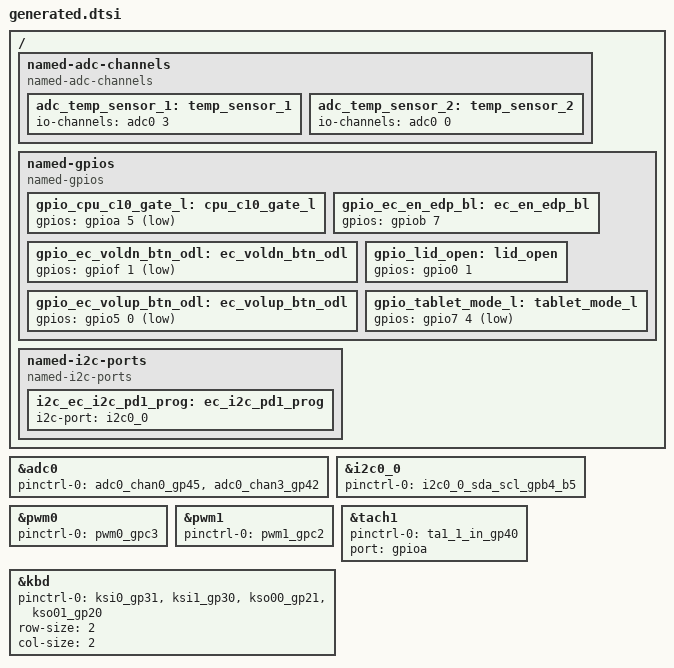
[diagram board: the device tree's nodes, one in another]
/* Copyright 2026 The ChromiumOS Authors
 * Use of this source code is governed by a BSD-style license that can be
 * found in the LICENSE file.
 *
 * This file is auto-generated - do not edit!
 */

/ {

	named-adc-channels {
		compatible = "named-adc-channels";

		adc_temp_sensor_1: temp_sensor_1 {
			io-channels = <&adc0 3>;
		};
		adc_temp_sensor_2: temp_sensor_2 {
			io-channels = <&adc0 0>;
		};
	};

	named-gpios {
		compatible = "named-gpios";

		gpio_cpu_c10_gate_l: cpu_c10_gate_l {
			gpios = <&gpioa 5 (GPIO_INPUT | GPIO_ACTIVE_LOW)>;
		};
		gpio_ec_en_edp_bl: ec_en_edp_bl {
			gpios = <&gpiob 7 (GPIO_OUTPUT | GPIO_ACTIVE_HIGH | GPIO_OUTPUT_INIT_HIGH)>;
		};
		gpio_ec_voldn_btn_odl: ec_voldn_btn_odl {
			gpios = <&gpiof 1 (GPIO_INPUT | GPIO_ACTIVE_LOW)>;
		};
		gpio_ec_volup_btn_odl: ec_volup_btn_odl {
			gpios = <&gpio5 0 (GPIO_INPUT | GPIO_ACTIVE_LOW)>;
		};
		gpio_lid_open: lid_open {
			gpios = <&gpio0 1 (GPIO_INPUT | GPIO_ACTIVE_HIGH)>;
		};
		gpio_tablet_mode_l: tablet_mode_l {
			gpios = <&gpio7 4 (GPIO_INPUT | GPIO_ACTIVE_LOW)>;
		};
	};

	named-i2c-ports {
		compatible = "named-i2c-ports";

		i2c_ec_i2c_pd1_prog: ec_i2c_pd1_prog {
			i2c-port = <&i2c0_0>;
		};
	};

};

&adc0 {
	status = "okay";
	pinctrl-0 = <
		&adc0_chan0_gp45
		&adc0_chan3_gp42
	>;
	pinctrl-names = "default";
};

&i2c0_0 {
	status = "okay";
	pinctrl-0 = <&i2c0_0_sda_scl_gpb4_b5>;
	pinctrl-names = "default";
};

&pwm0 {
	status = "okay";
	pinctrl-0 = <&pwm0_gpc3>;
	pinctrl-names = "default";
};

&pwm1 {
	status = "okay";
	pinctrl-0 = <&pwm1_gpc2>;
	pinctrl-names = "default";
};

&tach1 {
	status = "okay";
	pinctrl-0 = <&ta1_1_in_gp40>;
	pinctrl-names = "default";
	port = <&gpioa>;
};

&kbd {
	status = "okay";
	pinctrl-0 = <
		&ksi0_gp31
		&ksi1_gp30
		&kso00_gp21
		&kso01_gp20
	>;
	pinctrl-names = "default";
	row-size = <2>;
	col-size = <2>;
};
